# STM32F103 register map
STM32F103 medium-density performance line
Registers are 32-bit, read-write, reset 0x0 unless marked. A register's access mark holds for its fields unless they carry their own. Offsets are from the block's base; lines under a group give offsets from that group; [hi:lo] are bit positions; {n}, {i} and the like mark numbered series; 'fields as' and 'values as' point back to an identical list; <NAME> marks a mode.

## Memory map
0x40000000 TIM2 — General-purpose timer
0x40000400 TIM3
0x40000800 TIM4
0x40004400 USART2
0x40004800 USART3
0x40010000 AFIO — Alternate function I/O
0x40010800 GPIOA — General-purpose I/O
0x40010C00 GPIOB
0x40011000 GPIOC
0x40011400 GPIOD
0x40011800 GPIOE
0x40013800 USART1 — Universal synchronous asynchronous receiver transmitter
0x40021000 RCC — Reset and clock control
0x40022000 FLASH — Flash memory interface
0xE000E010 STK — SysTick timer
0xE000E100 NVIC — Nested vectored interrupt controller
0xE000ED00 SCB — System control block

## Interrupts
4 FLASH — Flash global interrupt
5 RCC — RCC global interrupt
28 TIM2 — TIM2 global interrupt
29 TIM3 — TIM3 global interrupt
30 TIM4 — TIM4 global interrupt
37 USART1 — USART1 global interrupt
38 USART2 — USART2 global interrupt
39 USART3 — USART3 global interrupt

## TIM2 — General-purpose timer
Base 0x40000000
Same registers: TIM3 0x40000400, TIM4 0x40000800
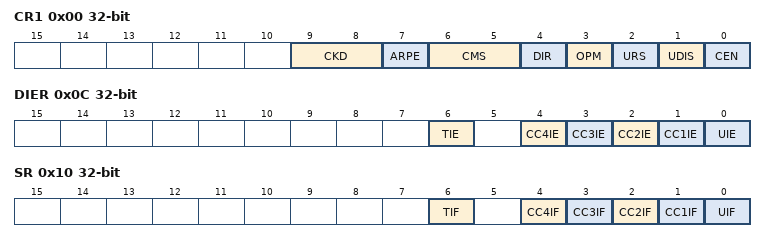
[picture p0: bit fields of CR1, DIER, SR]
0x00 CR1 — Control register 1
  [9:8] CKD — Clock division
  [7] ARPE — Auto-reload preload enable
  [6:5] CMS — Center-aligned mode selection
  [4] DIR — Direction
    0=Up (upcounter); 1=downcounter
  [3] OPM — One-pulse mode
  [2] URS — Update request source
  [1] UDIS — Update disable
  [0] CEN — Counter enable
0x04 CR2 — Control register 2
0x08 SMCR — Slave mode control register
0x0C DIER — DMA/interrupt enable register
  [6] TIE — Trigger interrupt enable
  [n] CC{n}IE (n=1..4) — Capture/compare {n} interrupt enable
  [0] UIE — Update interrupt enable
0x10 SR — Status register
  [6] TIF — Trigger interrupt flag
  [n] CC{n}IF (n=1..4) — Capture/compare {n} interrupt flag
  [0] UIF — Update interrupt flag
0x14 EGR wo — Event generation register
  [0] UG — Update generation
0x18 CCMR1 — Capture/compare mode register 1
0x1C CCMR2 — Capture/compare mode register 2
0x20 CCER — Capture/compare enable register
0x24 CNT — Counter
  [15:0] CNT — Counter value
0x28 PSC — Prescaler
  [15:0] PSC — Prescaler value
0x2C ARR reset 0xFFFF — Auto-reload register
  [15:0] ARR — Auto-reload value
{0x30+4i} CCR{i} (i=1..4) — Capture/compare register {i}
0x48 DCR — DMA control register
0x4C DMAR — DMA address for full transfer

## AFIO — Alternate function I/O
Base 0x40010000
0x00 EVCR — Event control register
0x04 MAPR — AF remap and debug I/O configuration register
  [26:24] SWJ_CFG — Serial wire JTAG configuration
{0x4+4i} EXTICR{i} (i=1..4) — External interrupt configuration register {i}

## GPIOA — General-purpose I/O
Base 0x40010800
Same registers: GPIOB 0x40010C00, GPIOC 0x40011000, GPIOD 0x40011400, GPIOE 0x40011800
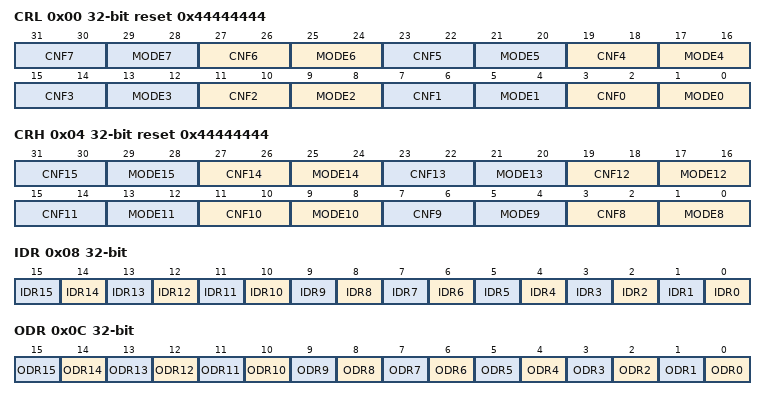
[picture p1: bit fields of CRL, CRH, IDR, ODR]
0x00 CRL reset 0x44444444 — Port configuration register low
  [4n+3:4n+2] CNF{n} (n=0..7) — Configuration of pin {n}: analog, floating or pull input; push-pull, open-drain or alternate function output
  [4n+1:4n] MODE{n} (n=0..7) — Mode of pin {n}
    0=Input; 1=Output10MHz; 2=Output2MHz; 3=Output50MHz
0x04 CRH reset 0x44444444 — Port configuration register high
  [4n-29:4n-30] CNF{n} (n=8..15) — Configuration of pin {n}: analog, floating or pull input; push-pull, open-drain or alternate function output
  [4n-31:4n-32] MODE{n} (n=8..15) — Mode of pin {n}
    0=Input; 1=Output10MHz; 2=Output2MHz; 3=Output50MHz
0x08 IDR ro — Port input data register
  [n] IDR{n} (n=0..15) — Input data of pin {n}
0x0C ODR — Port output data register
  [n] ODR{n} (n=0..15) — Output data of pin {n}
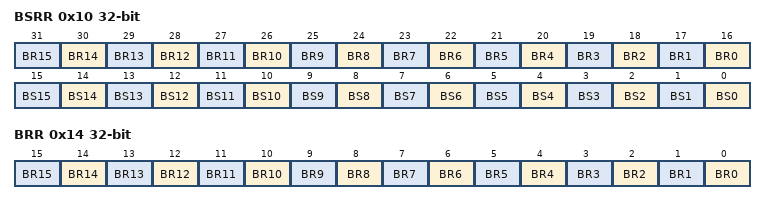
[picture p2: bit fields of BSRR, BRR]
0x10 BSRR wo — Port bit set/reset register
  [n+16] BR{n} (n=0..15) — Reset pin {n}
  [n] BS{n} (n=0..15) — Set pin {n}
0x14 BRR wo — Port bit reset register
  [n] BR{n} (n=0..15) — Reset pin {n}
0x18 LCKR — Port configuration lock register

## Notices in the file
Anlang from the register map of the reference manual (RM0008). Part
of Anlang, MIT license.
